# netx90_app register map
File version: 1.0
CPU: CM4 r0p1, little endian, MPU, FPU, 4 interrupt priority bits, 78 interrupts
Registers are 32-bit, read-write, reset 0x0 unless marked. A register's access mark holds for its fields unless they carry their own. Offsets are from the block's base; [hi:lo] are bit positions; lines under a group give offsets from that group; {n}, {i} and the like mark numbered series.

## cm4_scs
Base 0xE000E000
0x08 cm4_scs_actlr reset not defined — Auxiliary control register
  [31:0] bf_align0 — bitField alignment value for aeabi compatibility
0x10 cm4_scs_stcsr reset not defined — SysTick control and status register
  [31:0] bf_align0 — bitField alignment value for aeabi compatibility
0x14 cm4_scs_strvr reset not defined — SysTick Reload Value register
  [31:0] bf_align0 — bitField alignment value for aeabi compatibility
0x18 cm4_scs_stcvr reset not defined — SysTick current value register
  [31:0] bf_align0 — bitField alignment value for aeabi compatibility
0x1C cm4_scs_stcr ro reset not defined — SysTick calibration value register
  [31:0] bf_align0 — bitField alignment value for aeabi compatibility
{0x100+4i} cm4_scs_nvic_iser{i} (i=0..2) — Interrupt set-enable register {i} Enables, or reads the enable state of a group of interrupts.
  [31:0] setena — For register cm4_scs_nvic_iser[n], enables or shows the current enabled state of interrupt (m+(32*n)): 0: On reads, interrupt disabled. On writes, no effect. 1: On reads, interrupt enabled. On writes, enable interrupt. Software can enable multiple interrupts in a single write to cm4_scs_nvic_iser[n].
{0x180+4i} cm4_scs_nvic_icer{i} (i=0..2) — Interrupt clear-enable register {i} Disables, or reads the enable state of a group of interrupts.
  [31:0] clrena — For register cm4_scs_nvic_icer[n], disables or shows the current enabled state of interrupt (m+(32*n)): 0: On reads, interrupt disabled. On writes, no effect. 1: On reads, interrupt enabled. On writes, disable interrupt. Software can disable multiple interrupts in a single write to cm4_scs_nvic_icer[n].
{0x200+4i} cm4_scs_nvic_ispr{i} (i=0..2) — Interrupt set-pending register {i} For a group of interrupts, changes interrupt status to pending, or shows the current pending status.
  [31:0] setpend — For register cm4_scs_nvic_ispr[n], changes the state of interrupt (m+(32*n)) to pending, or shows whether the state of the interrupt is pending: 0: On reads, interrupt is not pending. On writes, no effect. 1: On reads, interrupt is pending. On writes, change state of interrupt to pending. Software can set multiple interrupts to pending state in a single write to cm4_scs_nvic_ispr[n].
{0x280+4i} cm4_scs_nvic_icpr{i} (i=0..2) — Interrupt clear-pending register {i} For a group of interrupts, clears the interrupt pending status, or shows the current pending status.
  [31:0] clrpend — For register cm4_scs_nvic_ispr[n], clears the pending state of interrupt (m+(32*n)), or shows whether the state of the interrupt is pending: 0: On reads, interrupt is not pending. On writes, no effect. 1: On reads, interrupt is pending. On writes, clears the pending state of interrupt. Software can clear the pending state of multiple interrupts in a single write to cm4_scs_nvic_icpr[n].
{0x300+4i} cm4_scs_nvic_iabr{i} ro (i=0..2) — Interrupt active bit register {i} For a group of 32 interrupts, shows whether each interrupt is active.
  [31:0] active — For register cm4_scs_nvic_iabr[n], shows whether interrupt (m+(32*n)) is active.
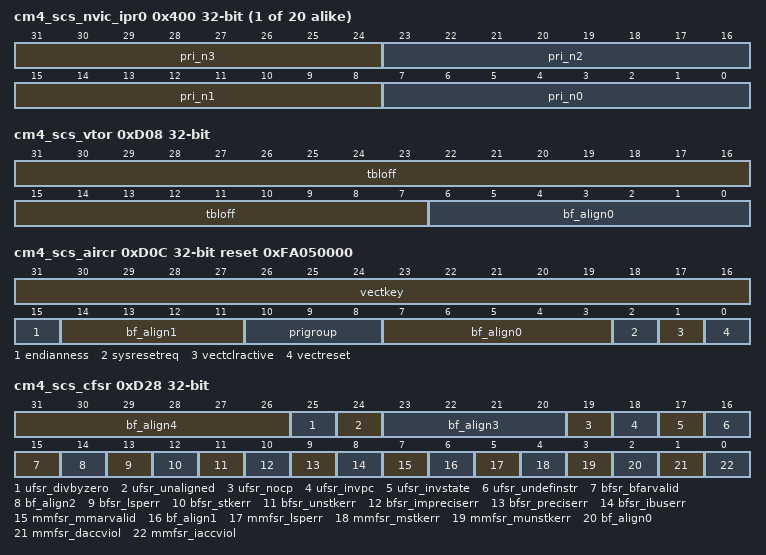
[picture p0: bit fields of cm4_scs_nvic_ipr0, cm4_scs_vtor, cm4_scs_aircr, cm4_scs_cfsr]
{0x400+4i} cm4_scs_nvic_ipr{i} (i=0..19) — Interrupt priority register {i} Sets or reads interrupt priorities.
  [31:24] pri_n3 — For register cm4_scs_nvic_ipr[n], priority of interrupt number 4n+3.
  [23:16] pri_n2 — For register cm4_scs_nvic_ipr[n], priority of interrupt number 4n+2.
  [15:8] pri_n1 — For register cm4_scs_nvic_ipr[n], priority of interrupt number 4n+1.
  [7:0] pri_n0 — For register cm4_scs_nvic_ipr[n], priority of interrupt number 4n.
0xD00 cm4_scs_cpuid ro reset not defined — CPUID base register
  [31:0] bf_align0 — bitField alignment value for aeabi compatibility
0xD04 cm4_scs_icsr reset not defined — Interrupt control and state register
  [31:0] bf_align0 — bitField alignment value for aeabi compatibility
0xD08 cm4_scs_vtor (reset mask 0xFFFFFF80) — Vector table offset register Holds the vector table address.
  [31:7] tbloff — Bits[31:7] of the vector table address.
  [6:0] bf_align0 — bitField alignment value for aeabi compatibility
0xD0C cm4_scs_aircr reset 0xFA050000 (reset mask 0xFFFF8707) — Application interrupt and reset control reister Sets or returns interrupt control data.
  [31:16] vectkey — Vector Key. Register writes must write 0x05FA to this field, otherwise the write is ignored. On reads, returns 0xFA05.
  [15] endianness — Indicates the memory system endianness: 0 - Little endian, 1 - Big endian. This bit is static or configured by a hardware input on reset. This bit is read only.
  [14:11] bf_align1 — bitField alignment value for aeabi compatibility
  [10:8] prigroup — Priority grouping, indicates the binary point position.
  [7:3] bf_align0 — bitField alignment value for aeabi compatibility
  [2] sysresetreq — System Reset Request. Writing 1 to this bit asserts a signal to the external system to request a Local reset. A Local or Power-on reset clears this bit to 0.
  [1] vectclractive — Writing 1 to this bit clears all active state information for fixed and configurable exceptions. This includes clearing the IPSR to zero. The effect of writing a 1 to this bit if the processor is not halted in Debug state is UNPREDICTABLE. This bit is write only.
  [0] vectreset — Writing 1 to this bit causes a local system reset. This bit self-clears. The effect of writing a 1 to this bit if the processor is not halted in Debug state is UNPREDICTABLE. When the processor is halted in Debug state, if a write to the register writes a 1 to both VECTRESET and SYSRESETREQ, the behavior is UNPREDICTABLE. This bit is write only. Note: The netx90 doesn't support a local system reset. Writing 1 results in UNPREDICTABLE behaviour of the whole system! Use sysresetreq instead!
0xD10 cm4_scs_scr reset not defined — System control Register
  [31:0] bf_align0 — bitField alignment value for aeabi compatibility
0xD14 cm4_scs_ccr reset not defined — Configuration and control Register
  [31:0] bf_align0 — bitField alignment value for aeabi compatibility
{0xD14+4i} cm4_scs_shpr{i} reset not defined (i=1..3) — System Handler Priority Register {i}
  [31:0] bf_align0 — bitField alignment value for aeabi compatibility
0xD24 cm4_scs_shcsr reset not defined — System Handler Control and State Register
  [31:0] bf_align0 — bitField alignment value for aeabi compatibility
0xD28 cm4_scs_cfsr (reset mask 0x30FBFBB) — Configurable Fault Status Register Contains the three Configurable Fault Status Registers.
  [31:26] bf_align4 — bitField alignment value for aeabi compatibility
  [25] ufsr_divbyzero — Divide by zero error has occurred.
  [24] ufsr_unaligned — Unaligned access error has occurred. Multi-word accesses always fault if not word aligned. Software can configure unaligned word and halfword accesses to fault, by enabling UNALIGN_TRP in the CCR.
  [23:20] bf_align3 — bitField alignment value for aeabi compatibility
  [19] ufsr_nocp — A coprocessor access error has occurred. This shows that the coprocessor is disabled or not present.
  [18] ufsr_invpc — An integrity check error has occurred on EXC_RETURN.
  [17] ufsr_invstate — Instruction executed with invalid EPSR.T or EPSR.IT field.
  [16] ufsr_undefinstr — The processor has attempted to execute an undefined instruction. This might be an undefined instruction associated with an enabled coprocessor.
  [15] bfsr_bfarvalid — BFAR has valid contents.
  [14] bf_align2 — bitField alignment value for aeabi compatibility
  [13] bfsr_lsperr — A bus fault occurred during FP lazy state preservation.
  [12] bfsr_stkerr — A derived bus fault has occurred on exception entry.
  [11] bfsr_unstkerr — A derived bus fault has occurred on exception return.
  [10] bfsr_impreciserr — Imprecise data access error has occurred.
  [9] bfsr_preciserr — A precise data access error has occurred, and the processor has written the faulting address to the BFAR.
  [8] bfsr_ibuserr — A bus fault on an instruction prefetch has occurred. The fault is signaled only if the instruction is issued.
  [7] mmfsr_mmarvalid — MMFAR has valid contents.
  [6] bf_align1 — bitField alignment value for aeabi compatibility
  [5] mmfsr_lsperr — A MemManage fault occurred during FP lazy state preservation.
  [4] mmfsr_mstkerr — A derived MemManage fault occurred on exception entry.
  [3] mmfsr_munstkerr — A derived MemManage fault occurred on exception return.
  [2] bf_align0 — bitField alignment value for aeabi compatibility
  [1] mmfsr_daccviol — Data access violation. The MMFAR shows the data address that the load or store tried to access.
  [0] mmfsr_iaccviol — MPU or Execute Never (XN) default memory map access violation on an instruction fetch has occurred. The fault is signalled only if the instruction is issued.
0xD2C cm4_scs_hfsr reset not defined — HardFault Status Register
  [31:0] bf_align0 — bitField alignment value for aeabi compatibility
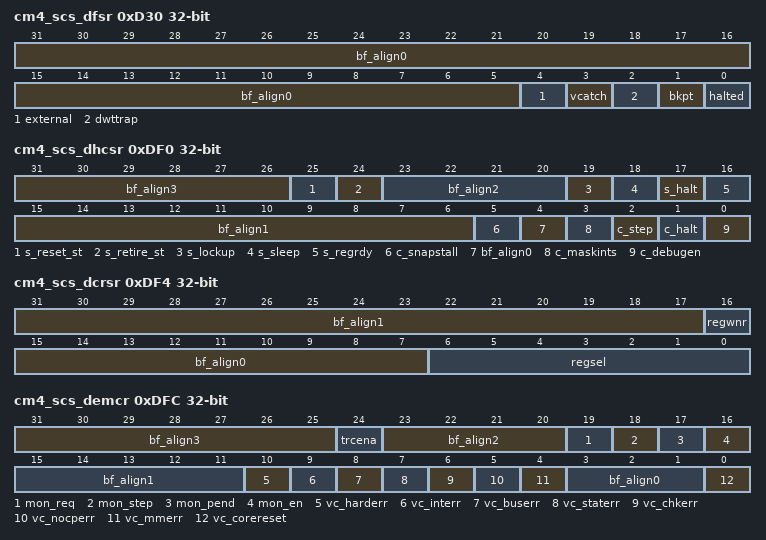
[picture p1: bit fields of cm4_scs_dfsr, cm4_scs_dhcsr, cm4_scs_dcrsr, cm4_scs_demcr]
0xD30 cm4_scs_dfsr (reset mask 0x1F) — Debug fault status Register Shows which debug event occurred. Note: Writing 1 to a register bit clears the bit to 0.
  [31:5] bf_align0 — bitField alignment value for aeabi compatibility
  [4] external — Indicates a debug event generated because of the assertion of an external debug request.
  [3] vcatch — Indicates triggering of a Vector catch.
  [2] dwttrap — Indicates a debug event generated by the DWT.
  [1] bkpt — Indicates a debug event generated by BKPT instruction execution or a breakpoint match in FPB.
  [0] halted — Indicates a debug event generated by either: - A C_HALT or C_STEP request, triggered by a write to the DHCSR. - A step request triggered by setting DEMCR.MON_STEP to 1.
0xD34 cm4_scs_mmfar reset not defined — MemManage Faul Address Register
  [31:0] bf_align0 — bitField alignment value for aeabi compatibility
0xD38 cm4_scs_bfar reset not defined — BusFault Address Register
  [31:0] bf_align0 — bitField alignment value for aeabi compatibility
0xD3C cm4_scs_afsr reset not defined — Auxiliary Fault Status Register
  [31:0] bf_align0 — bitField alignment value for aeabi compatibility
0xD88 cm4_scs_cpacr reset not defined — Coprocessor Access Control Register
  [31:0] bf_align0 — bitField alignment value for aeabi compatibility
0xDF0 cm4_scs_dhcsr (reset mask 0x30F002F) — Debug halting control and status register Controls halting debug. Note: On writes bits 31-16 (dbgkey) must be set to 0xA05F.
  [31:26] bf_align3 — bitField alignment value for aeabi compatibility
  [25] s_reset_st — Indicates whether the processor has been reset since the last read of DHCSR. This is a sticky bit, that clears to 0 on a read of DHCSR. This bit is read-only.
  [24] s_retire_st — Set to 1 every time the processor retires one or more instructions. This is a sticky bit, that clears to 0 on a read of DHCSR. The architecture does not define precisely when this bit is set to 1. It requires only that this happen periodically in Non-debug state to indicate that software execution is progressing. This bit is UNKNOWN after a Power-on or Local reset, but then is set to 1 as soon as the processor executes and retires an instruction. This bit is read-only.
  [23:20] bf_align2 — bitField alignment value for aeabi compatibility
  [19] s_lockup — Indicates whether the processor is locked up because of an unrecoverable exception. This bit can only be read as 1 by a remote debugger, using the DAP. The value of 1 indicates that the processor is running but locked up. The bit clears to 0 when the processor enters Debug state. This bit is read-only.
  [18] s_sleep — Indicates whether the processor is sleeping. The debugger must set the C_HALT bit to 1 to gain control, or wait for an interrupt or other wakeup event to wakeup the system. This bit is read-only.
  [17] s_halt — Indicates whether the processor is in Debug state. This bit is read-only.
  [16] s_regrdy — A handshake flag for transfers through the DCRDR: - Writing to DCRSR clears the bit to 0. - Completion of the DCRDR transfer then sets the bit to 1. For more information about DCRDR transfers see Debug Core Register Data Register, DCRDR. This bit is valid only when the processor is in Debug state, otherwise the bit is UNKNOWN. This bit is read-only.
  [15:6] bf_align1 — bitField alignment value for aeabi compatibility
  [5] c_snapstall — Allow imprecise entry to Debug state. The actions on writing to this bit are: - 0: No action. - 1: Allow imprecise entry to Debug state, for example by forcing any stalled load or store instruction to complete. Setting this bit to 1 allows a debugger to request imprecise entry to Debug state. The effect of setting this bit to 1 is UNPREDICTABLE unless the DHCSR write also sets C_DEBUGEN and C_HALT to 1. This means that if the processor is not already in Debug stateit enters Debug state when the stalled instruction completes. Writing 1 to this bit makes the state of the memory system UNPREDICTABLE. Therefore, if a debugger writes 1 to this bit it must reset the processor before leaving Debug state. Note: - A debugger can write to the DHCSR to clear this bit to 0. However, this does not remove the UNPREDICTABLE state of the memory system caused by setting C_SNAPSTALL to 1. - The architecture does not guarantee that setting this bit to 1 will force entry to Debug state. - ARM strongly recommends that a value of 1 is never written to C_SNAPSTALL when the processor is in Debug state.
  [4] bf_align0 — bitField alignment value for aeabi compatibility
  [3] c_maskints — When debug is enabled, the debugger can write to this bit to mask PendSV, SysTick and external configurable interrupts: - 0: Do not mask. - 1: Mask PendSV, SysTick and external configurable interrupts. The effect of any attempt to change the value of this bit is UNPREDICTABLE unless both: - Before the write to DHCSR, the value of the C_HALT bit is 1. - The write to the DHCSR that changes the C_MASKINTS bit also writes 1 to the C_HALT bit. This means that a single write to DHCSR cannot set the C_HALT to 0 and change the value of the C_MASKINTS bit. The bit does not affect NMI. When DHCSR.C_DEBUGEN is set to 0, the value of this bit is UNKNOWN. This bit is UNKNOWN after a Power-on reset.
  [2] c_step — Processor step bit. The effects of writes to this bit are: - 0: No effect. - 1: Single step enabled. This bit is UNKNOWN after a Power-on reset.
  [1] c_halt — Processor halt bit. The effects of writes to this bit are: - 0: Causes the processor to leave Debug state, if in Debug state. - 1: Halt the processor. This bit is UNKNOWN after a Power-on reset, and is 0 after a Local reset.
  [0] c_debugen — Halting debug enable bit. If a debugger writes to DHCSR to change the value of this bit from 0 to 1, it must also write 0 to the C_MASKINTS bit, otherwise behavior is UNPREDICTABLE. This bit can only be written by the DAP, it ignores writes from software.
0xDF4 cm4_scs_dcrsr wo (reset mask 0x1007F) — Debug core register selector register With the DCRDR, the DCRSR provides debug access to the ARM core registers, special-purpose registers, and Floating-point extension registers. A write to DCRSR specifies the register to transfer, whether the transfer is a read or a write, and starts the transfer.
  [31:17] bf_align1 — bitField alignment value for aeabi compatibility
  [16] regwnr — Specifies the access type for the transfer: 0 : Read. 1 : Write.
  [15:7] bf_align0 — bitField alignment value for aeabi compatibility
  [6:0] regsel — Specifies the ARM core register, special-purpose register, or Floating-point extension register, to transfer: { | 0 - 12 ARM core registers R0-R12. 13 The current SP. See also values 17 (MSP) and 18 (PSP). 14 LR. 15 DebugReturnAddress. 16 xPSR. 17 Main stack pointer, MSP. 18 Process stack pointer, PSP. 20 Bits[31:24]: CONTROL, Bits[23:16]: FAULTMASK, Bits[15:8]: BASEPRI, Bits[7:0]: PRIMASK. In each field, the valid bits are packed with leading zeros. For example, FAULTMASK is always a single bit, DCRDR[16], and DCRDR[23:17] is 0. 33 Floating-point Status and Control Register, FPSCR. 64 - 95 FP registers S0-S31. } All other values are Reserved. If the processor does not implement the FP extension the REGSEL field is bits[4:0], and bits[6:5] are Reserved, SBZ.
0xDF8 cm4_scs_dcrdr — Debug core register data register With the DCRSR, the DCRDR provides debug access to the ARM core registers, special-purpose registers, and Floating-point extension registers. The DCRDR is the data register for these accesses. Used on its own, the DCRDR provides a message passing resource between an external debugger and a debug agent running on the processor. Note: The architecture does not define any handshaking mechanism for this use of DCRDR.
  [31:0] dbgtmp — Data temporary cache, for reading and writing the ARM core registers, special-purpose registers, and Floating-point extension registers.
0xDFC cm4_scs_demcr (reset mask 0x10F07F1) — Debug exception and monitor control register Manages vector catch behavior and DebugMonitor handling when debugging.
  [31:25] bf_align3 — bitField alignment value for aeabi compatibility
  [24] trcena — Global enable for all DWT and ITM features: - 0: DWT and ITM units disabled. - 1: DWT and ITM units enabled. If the DWT and ITM units are not implemented, this bit is UNK/SBZP. When TRCENA is set to 0: - DWT registers return UNKNOWN values on reads. Whether the processor ignores writes to the DWT unit is IMPLEMENTATION DEFINED. - ITM registers return UNKNOWN values on reads. Whether the processor ignores writes to the ITM unit is IMPLEMENTATION DEFINED. Setting this bit to 0 might not stop all events. To ensure all events are stopped, software must set all DWT and ITM feature enable bits to 0, and then set this bit to 0.
  [23:20] bf_align2 — bitField alignment value for aeabi compatibility
  [19] mon_req — DebugMonitor semaphore bit. The processor does not use this bit. The monitor software defines the meaning and use of this bit.
  [18] mon_step — When MON_EN is set to 0, this feature is disabled and the processor ignores MON_STEP. When MON_EN is set to 1, the meaning of MON_STEP is: - 0: Do not step the processor. - 1: Step the processor. Setting this bit to 1 makes the step request pending. The effect of changing this bit at an execution priority that is lower than the priority of the DebugMonitor exception is UNPREDICTABLE.
  [17] mon_pend — Sets or clears the pending state of the DebugMonitor exception: - 0: Clear the status of the DebugMonitor exception to not pending. - 1: Set the status of the DebugMonitor exception to pending. When the DebugMonitor exception is pending it becomes active subject to the exception priority rules. A debugger can use this bit to wakeup the monitor using the DAP. The effect of setting this bit to 1 is not affected by the value of the MON_EN bit. A debugger can set MON_PEND to 1, and force the processor to take a DebugMonitor exception, even when MON_EN is set to 0.
  [16] mon_en — Enable the DebugMonitor exception. If DHCSR.C_DEBUGEN is set to 1, the processor ignores the value of this bit.
  [15:11] bf_align1 — bitField alignment value for aeabi compatibility
  [10] vc_harderr — Enable halting debug trap on a HardFault exception. If DHCSR.C_DEBUGEN is set to 0, the processor ignores the value of this bit.
  [9] vc_interr — Enable halting debug trap on a fault occurring during exception entry or exception return. If DHCSR.C_DEBUGEN is set to 0, the processor ignores the value of this bit.
  [8] vc_buserr — Enable halting debug trap on a BusFault exception. If DHCSR.C_DEBUGEN is set to 0, the processor ignores the value of this bit.
  [7] vc_staterr — Enable halting debug trap on a UsageFault exception caused by a state information error, for example an Undefined Instruction exception. If DHCSR.C_DEBUGEN is set to 0, the processor ignores the value of this bit.
  [6] vc_chkerr — Enable halting debug trap on a UsageFault exception caused by a checking error, for example an alignment check error. If DHCSR.C_DEBUGEN is set to 0, the processor ignores the value of this bit.
  [5] vc_nocperr — Enable halting debug trap on a UsageFault caused by an access to a Coprocessor. If DHCSR.C_DEBUGEN is set to 0, the processor ignores the value of this bit.
  [4] vc_mmerr — Enable halting debug trap on a MemManage exception. If DHCSR.C_DEBUGEN is set to 0, the processor ignores the value of this bit.
  [3:1] bf_align0 — bitField alignment value for aeabi compatibility
  [0] vc_corereset — Enable Reset Vector Catch. This causes a Local reset to halt a running system. If DHCSR.C_DEBUGEN is set to 0, the processor ignores the value of this bit.
0xFD0 cm4_scs_pidr4 ro reset not defined — Peripheral ID Register 4
  [31:0] bf_align0 — bitField alignment value for aeabi compatibility
{0xFE0+4i} cm4_scs_pidr{i} ro reset not defined (i=0..3) — Peripheral ID Register {i}
  [31:0] bf_align0 — bitField alignment value for aeabi compatibility
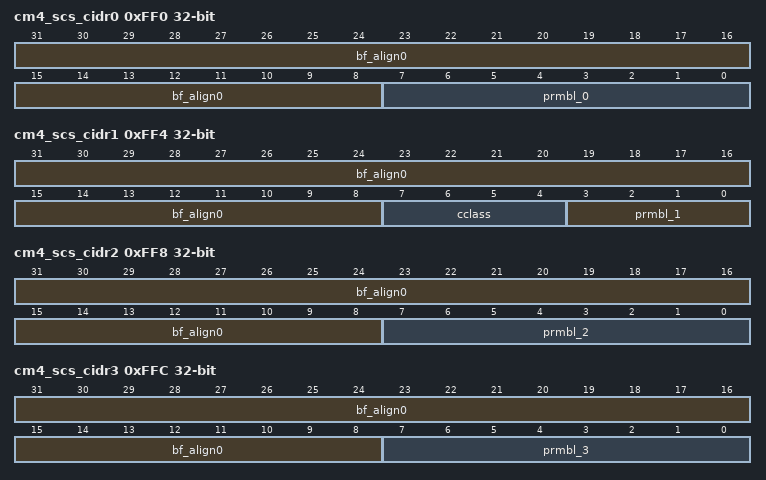
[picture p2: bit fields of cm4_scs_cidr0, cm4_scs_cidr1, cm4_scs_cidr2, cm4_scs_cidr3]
0xFF0 cm4_scs_cidr0 ro (reset mask 0xFF) — Component ID Register 0
  [31:8] bf_align0 — bitField alignment value for aeabi compatibility
  [7:0] prmbl_0 — Preamble byte 0.
0xFF4 cm4_scs_cidr1 ro (reset mask 0xFF) — Component ID Register 1
  [31:8] bf_align0 — bitField alignment value for aeabi compatibility
  [7:4] cclass — Component class.
  [3:0] prmbl_1 — Preamble bits[11:8].
0xFF8 cm4_scs_cidr2 ro (reset mask 0xFF) — Component ID Register 2
  [31:8] bf_align0 — bitField alignment value for aeabi compatibility
  [7:0] prmbl_2 — Preamble byte 2.
0xFFC cm4_scs_cidr3 ro (reset mask 0xFF) — Component ID Register 3
  [31:8] bf_align0 — bitField alignment value for aeabi compatibility
  [7:0] prmbl_3 — Preamble byte 3.
